# cslr_mcbsp register map
Vendor: Texas Instruments
Peripheral module from a debugger description file (folder C5517).
Address unit: 16 bits
Registers are 16-bit, read-write, reset 0x0 unless marked. A register's access mark holds for its fields unless they carry their own. Offsets are as the file gives them; lines under a group give offsets from that group; [hi:lo] are bit positions; {n}, {i} and the like mark numbered series; 'fields as' and 'values as' point back to an identical list; <NAME> marks a mode.

## MCBSP — Multi Channel buffered serial port interfaces with audio devices
0x00 DRRL ro — Contains the Lower value received on the data bus
  [15:0] DR — Data receiver register value loaded from the RBR.
0x01 DRRU ro — Contains the upper value received on the data bus
  [15:0] DR — Data receiver register value loaded from the RBR.
0x04 DXRL — Contains the lower value to be loaded into the data transmit shift register
  [15:0] DX — Data transmit register value to be loaded into the data transmit shift register.
0x05 DXRU — contains the upper value to be loaded into the data transmit shift register
  fields as DXRL
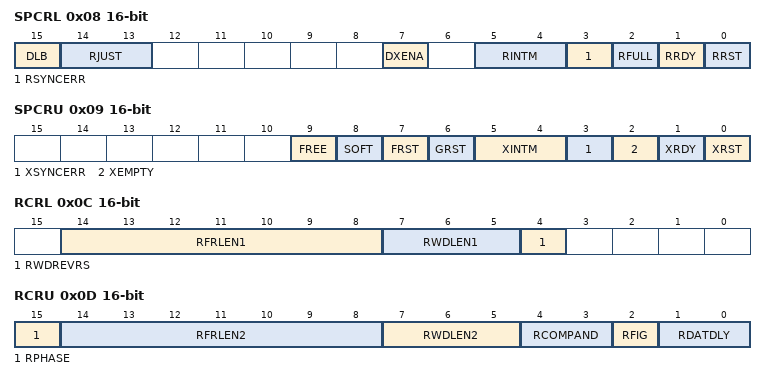
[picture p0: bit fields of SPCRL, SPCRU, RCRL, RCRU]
0x08 SPCRL access not given — This register contains configuration bits for McBSP desired operation
  [15] DLB rw — Digital Loop Back Mode enable bit.
    0=DISABLE (Digital loop back disabled); 1=ENABLE (Digital loop back enabled)
  [14:13] RJUST rw — Receive Sign-Extension and Justification Mode bit.
    0=RJZFMSB (right-justify and zero-fill MSBs in DRR); 1=RJSEMSB (right-justify and sign-extend MSBs in DRR); 2=LJZFLSB (left-justify and zero-fill LSBs in DRR)
  [7] DXENA rw — DX Enabler bit.
    0=OFF (DX enabler is off); 1=ON (DX enabler is on)
  [5:4] RINTM rw — Receive Interrupt mode select bits.
    0=RRDY (Receive interrupt generated by RRDY); 1=EOF (Receive interrupt generated by EOF); 2=NEWFS (Receive interrupt generated by NEWFS); 3=SYNCERR (Receive interrupt generated by SYNCERR)
  [3] RSYNCERR rw — Receive Synchronization Error bit.
    0=NOSYNCERR (No sync error detected by McBSP)
  [2] RFULL ro — Receive Shift Register (RSR) Full status.
    0=NOTFULL (RBR is not in overrun condition); 1=FULL (RBR is in overrun condition)
  [1] RRDY ro — Receiver Ready status bit.
    0=BUSY (Receiver is busy); 1=READY (Receiver is ready)
  [0] RRST rw — Receiver reset bit.
    0=DISABLE (Receiver in reset); 1=ENABLE (Receiver enabled)
0x09 SPCRU access not given — This register contains configuration bits for McBSP desired operation
  [9] FREE rw — Free running mode enable bit.
    0=DISABLE (Free running mode disabled); 1=ENABLE (Free running mode enabled)
  [8] SOFT rw — Soft mode select bit.
    0=DISABLE (SOFT mode is disabled); 1=ENABLE (SOFT mode is enabled)
  [7] FRST rw — Frame Sync Generator Reset bit.
    0=RESET (Frame Synchronization logic is reset); 1=NOTRESET (Frame Synchronization logic is active)
  [6] GRST rw — Sample Rate Generator Reset bit.
    0=RESET (Sample rate generator in reset); 1=NOTRESET (Sample rate generator out of reset)
  [5:4] XINTM rw — Transmit Interrupt mode selection bits.
    0=XRDY (Transmit interrupt generated by XRDY); 1=EOF (Transmit interrupt generated by EOF); 2=NEWFS (Transmit interrupt generated by NEWFS); 3=SYNCERR (Transmit interrupt generated by SYNCERR)
  [3] XSYNCERR rw — Transmit Synchronization Error bit.
    0=NOSYNCERR (No sync error detected by McBSP)
  [2] XEMPTY ro — Transmit Shift Register (XSR) Empty status bit.
    0=EMPTY (XSR is empty); 1=NOTEMPTY (XSR is not empty)
  [1] XRDY ro — Transmitter Ready status bit.
    0=BUSY (Transmitter is busy); 1=READY (Transmitter is ready)
  [0] XRST rw — Transmitter reset bit.
    0=DISABLE (Transmitter in reset); 1=ENABLE (Transmitter enabled)
0x0C RCRL access not given — Configure various parameters of receive operation
  [14:8] RFRLEN1 rw — Receive Frame Length 1.
  [7:5] RWDLEN1 rw — Receive Word Length 1 select bits.
    0=8BITS (Receive word length 8bits); 1=12BITS (Receive word length 12bits); 2=16BITS (Receive word length 16bits); 3=20BITS (Receive word length 20bits); 4=24BITS (Receive word length 24bits); 5=32BITS (Receive word length 32bits)
  [4] RWDREVRS rw — Receive 32-bit reversal feature select bit.
    0=DISABLE (32-bit reversal disabled); 1=ENABLE (32-bit reversal enabled)
0x0D RCRU — Configure various parameters of receive operation
  [15] RPHASE — Receive Phase selection bit.
    0=SINGLEPHASE (Single phase frame selected); 1=DUALPHASE (Dual phase frame selected)
  [14:8] RFRLEN2 — Receive Frame Length 2.
  [7:5] RWDLEN2 — Receive Word Length 2 select bits.
    values as RCRL.RWDLEN1
  [4:3] RCOMPAND — Receive Companding Mode bits.
    0=NCMSBFIRST (Receiver no companding, data transfer starts with MSB first); 1=NCLSBFIRST (Receiver no companding, 8-bit data, transfer starts with LSB first); 2=CULAW (Receiver compand using u-law for receive data); 3=CALAW (Receiver compand using A-law for receive data)
  [2] RFIG — Receive Frame Ignore bit.
    0=DISABLE (Receive Frame ignore disabled); 1=ENABLE (Receive Frame ignore enabled)
  [1:0] RDATDLY — Receive data delay bits.
    0=0BIT (0-bit data delay); 1=1BIT (1-bit data delay); 2=2BIT (2-bit data delay)
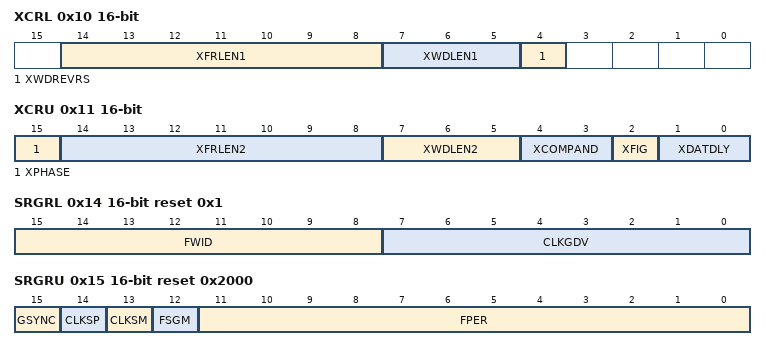
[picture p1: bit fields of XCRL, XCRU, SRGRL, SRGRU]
0x10 XCRL access not given — Configure various parameters of transmit operation
  [14:8] XFRLEN1 rw — Transmit Frame Length 1.
  [7:5] XWDLEN1 rw — Transmit Word Length 1 select bits.
    0=8BITS (Transmit word length 8bits); 1=12BITS (Transmit word length 12bits); 2=16BITS (Transmit word length 16bits); 3=20BITS (Transmit word length 20bits); 4=24BITS (Transmit word length 24bits); 5=32BITS (Transmit word length 32bits)
  [4] XWDREVRS rw — Transmit 32-bit reversal feature select bit.
    values as RCRL.RWDREVRS
0x11 XCRU — Configure various parameters of transmit operation
  [15] XPHASE — Transmit Phase selection bit.
    values as RCRU.RPHASE
  [14:8] XFRLEN2 — Transmit Frame Length 2.
  [7:5] XWDLEN2 — Transmit Word Length 2.
    values as XCRL.XWDLEN1
  [4:3] XCOMPAND — Transmit Companding Mode bits.
    0=NCMSBFIRST (Transmit no companding, data transfer starts with MSB first); 1=NCLSBFIRST (Transmit no companding, 8-bit data, transfer starts with LSB first); 2=CULAW (Transmit compand using u-law for transmit data); 3=CALAW (Transmit compand using A-law for transmit data)
  [2] XFIG — Transmit Frame Ignore bit.
    0=DISABLE (Transmit Frame ignore disabled); 1=ENABLE (Transmit Frame ignore enabled)
  [1:0] XDATDLY — Transmit data delay bits.
    values as RCRU.RDATDLY
0x14 SRGRL reset 0x1 — Controls the operation of various features of the sample rate generator
  [15:8] FWID — Frame width value
  [7:0] CLKGDV — Sample-rate generator clock divider value
0x15 SRGRU reset 0x2000 — Controls the operation of various features of the sample rate generator
  [15] GSYNC — Sample-rate generator clock synchronization bit
    0=FREERUN (the sample rate generator clock (CLKG) is free running.); 1=RUN (The sample rate generator clock (CLKG) is running)
  [14] CLKSP — CLKS polarity clock edge select bit
    0=RISINGEDGE (rising edge of CLKS generates CLKG and FSG); 0=FALLINGEDGE (falling edge of CLKS generates CLKG and FSG.)
  [13] CLKSM — Sample rate generator input clock mode select bits
    0=ZERO (Sample rate generator clock derived from the CLKS pin depending on SCLKME); 1=ONE (Sample rate generator clock derived from CPU clock depending on SCLKME)
  [12] FSGM — Sample-rate generator transmit frame-synchronization mode selection bits
    0=ZERO (Transmit frame sync signal (FSX) due to DXR-to-XSR copy); 1=ONE (Transmit frame sync signal driven by the sample rate generator frame sync signal, FSG)
  [11:0] FPER — Frame period value
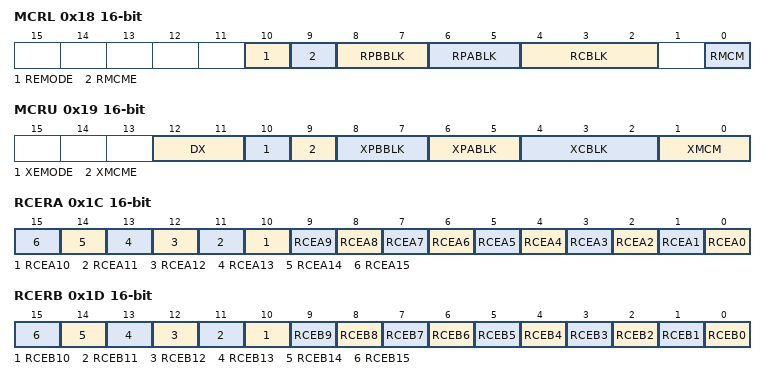
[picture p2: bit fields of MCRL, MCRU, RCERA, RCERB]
0x18 MCRL access not given — Control and Status bits for multichannel operation
  [10] REMODE rw — Receive Multi-channel mode selection bit
    0=ZERO (Traditional/32/128 channel operation); 1=ONE (512 channel mode with PDMA)
  [9] RMCME rw — Enhanced receive multichannel selection enable bits
    0=ZERO (Maximum 32 channels can be enabled at one time); 1=ONE (Maximum 128 channels can be enabled at one time)
  [8:7] RPBBLK rw — Receive Partition B Block bits
    0=BLOCK1 (Block 1-Channel 16 to channel 31); 1=BLOCK3 (Block 3-Channel 48 to channel 63); 2=BLOCK5 (Block 5-Channel 80 to channel 95); 3=BLOCK7 (Block 7-Channel 112 to channel 127)
  [6:5] RPABLK rw — Receive Partition A Block bits.
    0=BLOCK0 (Block 0-Channel 0 to channel 15); 1=BLOCK2 (Block 2-Channel 32 to channel 47); 2=BLOCK4 (Block 4-Channel 64 to channel 79); 3=BLOCK6 (Block 6-Channel 96 to channel 111)
  [4:2] RCBLK ro — Receive Current Block status bits
    0=BLOCK0 (Block 0. Channel 0 to channel 15); 1=BLOCK1 (Block 1. Channel 16 to channel 31); 2=BLOCK2 (Block 2. Channel 32 to channel 47); 3=BLOCK3 (Block 3. Channel 48 to channel 63); 4=BLOCK4 (Block 4. Channel 64 to channel 79); 5=BLOCK5 (Block 5. Channel 80 to channel 95); 6=BLOCK6 (Block 6. Channel 96 to channel 111); 7=BLOCK7 (Block 7. Channel 112 to channel 127)
  [0] RMCM rw — Receive Multi-channel Selection Enable bits
    0=ZERO (all 128 channels enabled); 1=ONE (all channels disabled by default. Required channels are selected by enabling RP(A/B)BLK and RCER(A/B) appropriately)
0x19 MCRU access not given — Control and Status bits for multichannel operation
  [12:11] DX rw — Transmit pin mode configuration, this is used to configure the DX pin state while the time slot is disabled
    0=ZERO (Hi-Z); 1=ONE (Driven as 1); 2=TWO (Driven as 0)
  [10] XEMODE rw — Transmit Multi-channel mode selection bit
    values as MCRL.REMODE
  [9] XMCME rw — Enhanced transmit multichannel selection enable bits
    values as MCRL.RMCME
  [8:7] XPBBLK rw — Transmit Partition B Block bits
    values as MCRL.RPBBLK
  [6:5] XPABLK rw — Transmit Partition A Block bits.
    values as MCRL.RPABLK
  [4:2] XCBLK ro — Transmit Current Block status bits
    values as MCRL.RCBLK
  [1:0] XMCM rw — Transmit Multi-channel Selection Enable bits
    0=ZERO (all 128 channels enabled); 1=ONE (all channels disabled by default. Required channels are selected by enabling XP(A/B)BLK and XCER(A/B) appropriately)
0x1C RCERA — Enhanced receive Channel Enable Partition A
  [n] RCEA{n} (n=0..15)
    0=DISABLE (Reception of channel {n} in an even-numbered block in partition A is disabled); 1=ENABLE (Reception of channel {n} in an even-numbered block in partition A is enabled)
0x1D RCERB — Enhanced receive Channel Enable Partition B
  [n] RCEB{n} (n=0..15)
    0=DISABLE (Reception of channel {n} in an odd-numbered block in partition B is disabled); 1=ENABLE (Reception of channel {n} in an odd-numbered block in partition B is enabled)
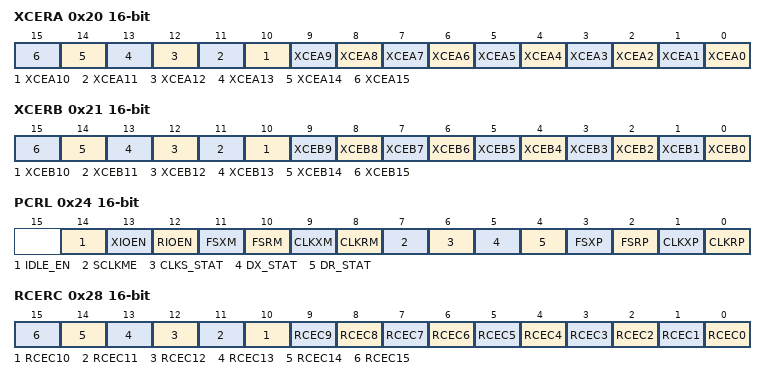
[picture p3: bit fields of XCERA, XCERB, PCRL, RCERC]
0x20 XCERA — Enhanced receive Channel Enable Register Partition A
  [n] XCEA{n} (n=0..15)
    0=DISABLE (Transmission of channel {n} in an even-numbered block in partition A is disabled); 1=ENABLE (Transmission of channel {n} in an even-numbered block in partition A is enabled)
0x21 XCERB — Enhanced receive Channel Enable Register Partition B
  [n] XCEB{n} (n=0..15)
    0=DISABLE (Transmission of channel {n} in an odd-numbered block in partition B is disabled); 1=ENABLE (Transmission of channel {n} in an odd-numbered block in partition B is enabled)
0x24 PCRL access not given — Configures serial port pin as General purpose input or output
  [14] IDLE_EN rw — Idle control bit for McBSP
    0=RUNNING (The McBSP is running); 1=IDLE (The McBSP is idle)
  [13] XIOEN rw — Transmit General Purpose I/O Mode only select bit
    0=NOTGPIO (DR,CLKS are not general purpose inputs, DX is not general purpose output and FS(R/X), CLK(R/X) are not general purpose I/Os.); 0=GPIO (DR,CLKS are general purpose inputs, DX is general purpose output and FS(R/X), CLK(R/X) are general purpose I/Os.)
  [12] RIOEN rw — Receive General Purpose I/O Mode only select bit
    values as XIOEN
  [11] FSXM rw — Transmit Frame Synchronization Mode
    0=ZERO (Frame synchronization signal derived from an external source); 1=ONE (Frame synchronization is determined by the Sample Rate Generator frame synchronization mode bit FSGM in the SRGR2)
  [10] FSRM rw — Receive Frame Synchronization Mode
    0=ZERO (Frame synchronization pulses generated by an external device. FSR is an input pin); 1=ONE (Frame synchronization generated internally by sample rate generator. FSR is an output pin except when GSYNC=1 in SRGR.)
  [9] CLKXM rw — Transmitter Clock Mode selection bit.
    0=ZERO (CLKX is an input pin and is driven by an external clock); 1=ONE (CLKX is an output pin and is driven by the internal sample-rate generator)
  [8] CLKRM rw — Receiver Clock Mode selection bit.
    0=ZERO (CLKR is an input pin and is driven by an external clock / Receive clock (not the CLKR pin) is driven by transmit clock (CLKX).); 1=ONE (CLKR is an output pin and is driven by the internal sample-rate generator or CLKR is an output pin and is driven by the transmit clock.)
  [7] SCLKME rw — Enhanced sample clock mode selection bit
    0=ZERO (Signal on CLKS or internal clock); 1=ONE (Signal on CLKR/CLKX pin)
  [6] CLKS_STAT ro — CLKS pin status bit.
    0=LOW (CLKS pin is at logic low); 1=HIGH (CLKS pin is at logic high)
  [5] DX_STAT rw — DX pin status bit.
    0=LOW (DX pin is at logic low); 1=HIGH (DX pin is at logic high)
  [4] DR_STAT ro — DR pin status bit
    0=LOW (DR pin is at logic low); 1=HIGH (DR pin is at logic high)
  [3] FSXP rw — Transmit Frame Synchronization Polarity
    0=ACTIVEHIGH (Frame synchronization pulse FSX is active high); 1=ACTIVELOW (Frame synchronization pulse FSX is active low)
  [2] FSRP rw — Receive Frame Synchronization Polarity
    0=ACTIVEHIGH (Frame synchronization pulse FSR is active high); 1=ACTIVELOW (Frame synchronization pulse FSR is active low)
  [1] CLKXP rw — Transmit Clock Polarity select bit
    0=RISINGEDGE (Transmit data sampled on rising edge of CLKX); 1=FALLINGEDGE (Transmit data sampled on falling edge of CLKX)
  [0] CLKRP rw — Receive Clock Polarity select bit
    0=FALLINGEDGE (Receive data sampled on falling edge of CLKR); 1=RISINGEDGE (Receive data sampled on rising edge of CLKR)
0x25 PCRU access not given — Configures serial port pin as General purpose input or output
0x28 RCERC — enhanced receive channel enable register
  [n] RCEC{n} (n=0..15)
    0=DISABLE (Reception of channel {n} in an even-numbered block in partition C is disabled); 1=ENABLE (Reception of channel {n} in an even-numbered block in partition C is enabled)
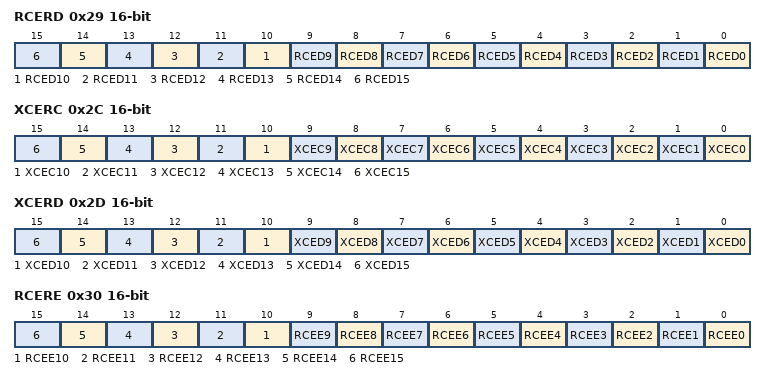
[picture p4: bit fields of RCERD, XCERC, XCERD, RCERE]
0x29 RCERD — enhanced receive channel enable register
  [n] RCED{n} (n=0..15)
    0=DISABLE (Reception of channel {n} in an odd-numbered block in partition D is disabled); 1=ENABLE (Reception of channel {n} in an odd-numbered block in partition D is enabled)
0x2C XCERC — enhanced transmit channel enable register
  [n] XCEC{n} (n=0..15)
    0=DISABLE (Transmission of channel {n} in an even-numbered block in partition C is disabled); 1=ENABLE (Transmission of channel {n} in an even-numbered block in partition C is enabled)
0x2D XCERD — enhanced transmit channel enable register
  [n] XCED{n} (n=0..15)
    0=DISABLE (Transmission of channel {n} in an odd-numbered block in partition D is disabled); 1=ENABLE (Transmission of channel {n} in an odd-numbered block in partition D is enabled)
0x30 RCERE — Enhanced Receive Channel Enable Register Partition E
  [n] RCEE{n} (n=0..15)
    0=DISABLE (Reception of channel {n} in an even-numbered block in partition E is disabled); 1=ENABLE (Reception of channel {n} in an even-numbered block in partition E is enabled)
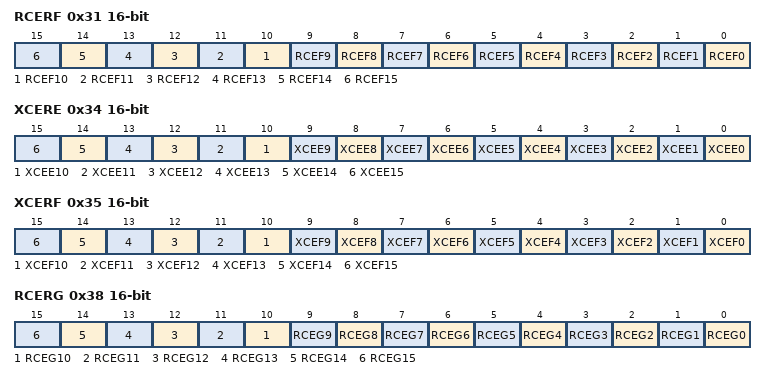
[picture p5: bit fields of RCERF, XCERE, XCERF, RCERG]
0x31 RCERF — Enhanced Receive Channel Enable Register Partition F
  [n] RCEF{n} (n=0..15)
    0=DISABLE (Reception of channel {n} in an odd-numbered block in partition F is disabled); 1=ENABLE (Reception of channel {n} in an odd-numbered block in partition F is enabled)
0x34 XCERE — Enhanced Transmit Channel Enable Register Partition E
  [n] XCEE{n} (n=0..15)
    0=DISABLE (Transmission of channel {n} in an even-numbered block in partition E is disabled); 1=ENABLE (Transmission of channel {n} in an even-numbered block in partition E is enabled)
0x35 XCERF — Enhanced Transmit Channel Enable Register Partition F
  [n] XCEF{n} (n=0..15)
    0=DISABLE (Transmission of channel {n} in an odd-numbered block in partition F is disabled); 1=ENABLE (Transmission of channel {n} in an odd-numbered block in partition F is enabled)
0x38 RCERG
  [n] RCEG{n} (n=0..15)
    0=DISABLE (Reception of channel {n} in an even-numbered block in partition G is disabled); 1=ENABLE (Reception of channel {n} in an even-numbered block in partition G is enabled)
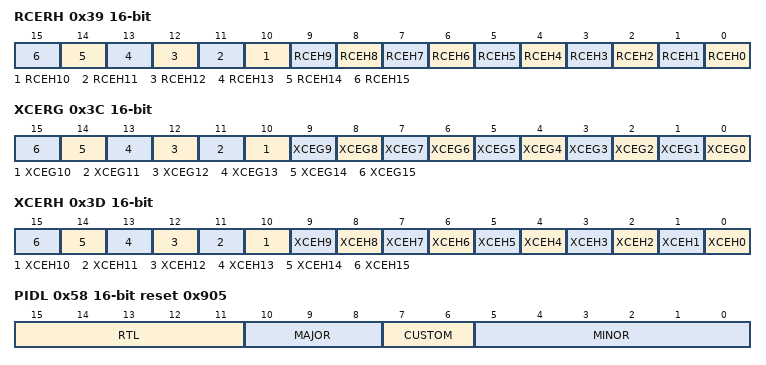
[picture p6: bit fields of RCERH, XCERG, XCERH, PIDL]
0x39 RCERH
  [n] RCEH{n} (n=0..15)
    0=DISABLE (Reception of channel {n} in an odd-numbered block in partition H is disabled); 1=ENABLE (Reception of channel {n} in an odd-numbered block in partition H is enabled)
0x3C XCERG — Enhnaced Transmit Channel Enable Register Partition G
  [n] XCEG{n} (n=0..15)
    0=DISABLE (Transmission of channel {n} in an even-numbered block in partition G is disabled); 1=ENABLE (Transmission of channel {n} in an even-numbered block in partition G is enabled)
0x3D XCERH — Enhnaced Transmit Channel Enable Register Partition H
  [n] XCEH{n} (n=0..15)
    0=DISABLE (Transmission of channel {n} in an odd-numbered block in partition H is disabled); 1=ENABLE (Transmission of channel {n} in an odd-numbered block in partition H is enabled)
0x40 REVTCR access not given
  [6:0] REVTCI ro — Receive channel event information bits
0x44 XEVTCR access not given
  [6:0] XEVTCI ro — Transmit channel event information bits
0x50 RSYNCCNT access not given — This register used for the super-frame synchronization, which is used to decide the number of frame synchronization pulse
  [6:0] RSYNCCNT rw — Frame synchronization count bits for super-frame synchronization
0x54 XSYNCCNT access not given — Transmit frame Synchronization Counter Register
  [6:0] XSYNCCNT rw — Frame synchronization count bits for super-frame synchronization
0x58 PIDL ro reset 0x905 — store versioning information used to identify the specific McBSP peripheral implemented in a particular device
  [15:11] RTL — Identifies the RTL version of the McBSP
  [10:8] MAJOR — Identifies the Major field value of the McBSP
  [7:6] CUSTOM — Identifies the Custom field value of the McBSP
  [5:0] MINOR — Identifies the Minor field value of the McBSP
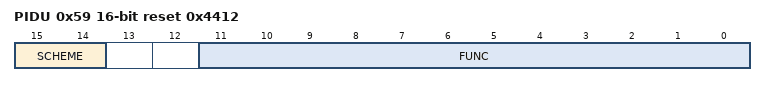
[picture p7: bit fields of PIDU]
0x59 PIDU access not given reset 0x4412 — store versioning information used to identify the specific McBSP peripheral implemented in a particular device
  [15:14] SCHEME ro — Identifes the Scheme field of peripheral
  [11:0] FUNC ro — Identifes the Func field of peripheral
